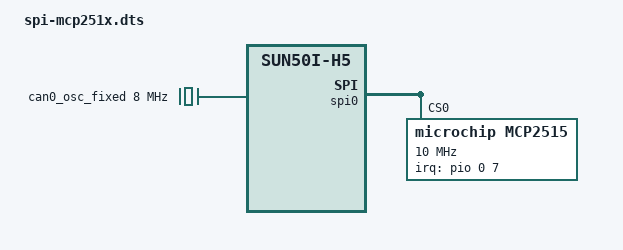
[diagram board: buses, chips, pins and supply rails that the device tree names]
/dts-v1/;
/plugin/;

/ {
	compatible = "allwinner,sun4i-a10", "allwinner,sun7i-a20", "allwinner,sun8i-h3", "allwinner,sun50i-a64", "allwinner,sun50i-h5";

	fragment@0 {
		target-path = "/clocks";
		__overlay__ {
			#address-cells = <1>;
			#size-cells = <1>;
			can0_osc_fixed: can0_osc_fixed {
				compatible = "fixed-clock";
				#clock-cells = <0>;
				clock-frequency  = <8000000>;
			};
		};
	};

	fragment@1 {
		target = <&pio>;
		__overlay__ {
			can0_pin_irq: can0_pin_irq {
				pins = "PA7";
				function = "irq";
				bias-pull-up;
			};
		};
	};

	fragment@2 {
		target = <&spi0>;
		__overlay__ {
			#address-cells = <1>;
			#size-cells = <0>;
			status = "okay";
			mcp2515 {
				reg = <0>;
				compatible = "microchip,mcp2515";
				pinctrl-names = "default";
				pinctrl-0 = <&can0_pin_irq>;
				spi-max-frequency = <10000000>;
				interrupt-parent = <&pio>;
				interrupts = <0 7 2>; /* PA7 IRQ_TYPE_EDGE_FALLING */
				clocks = <&can0_osc_fixed>;
				status = "okay";
			};
		};
	};
};
